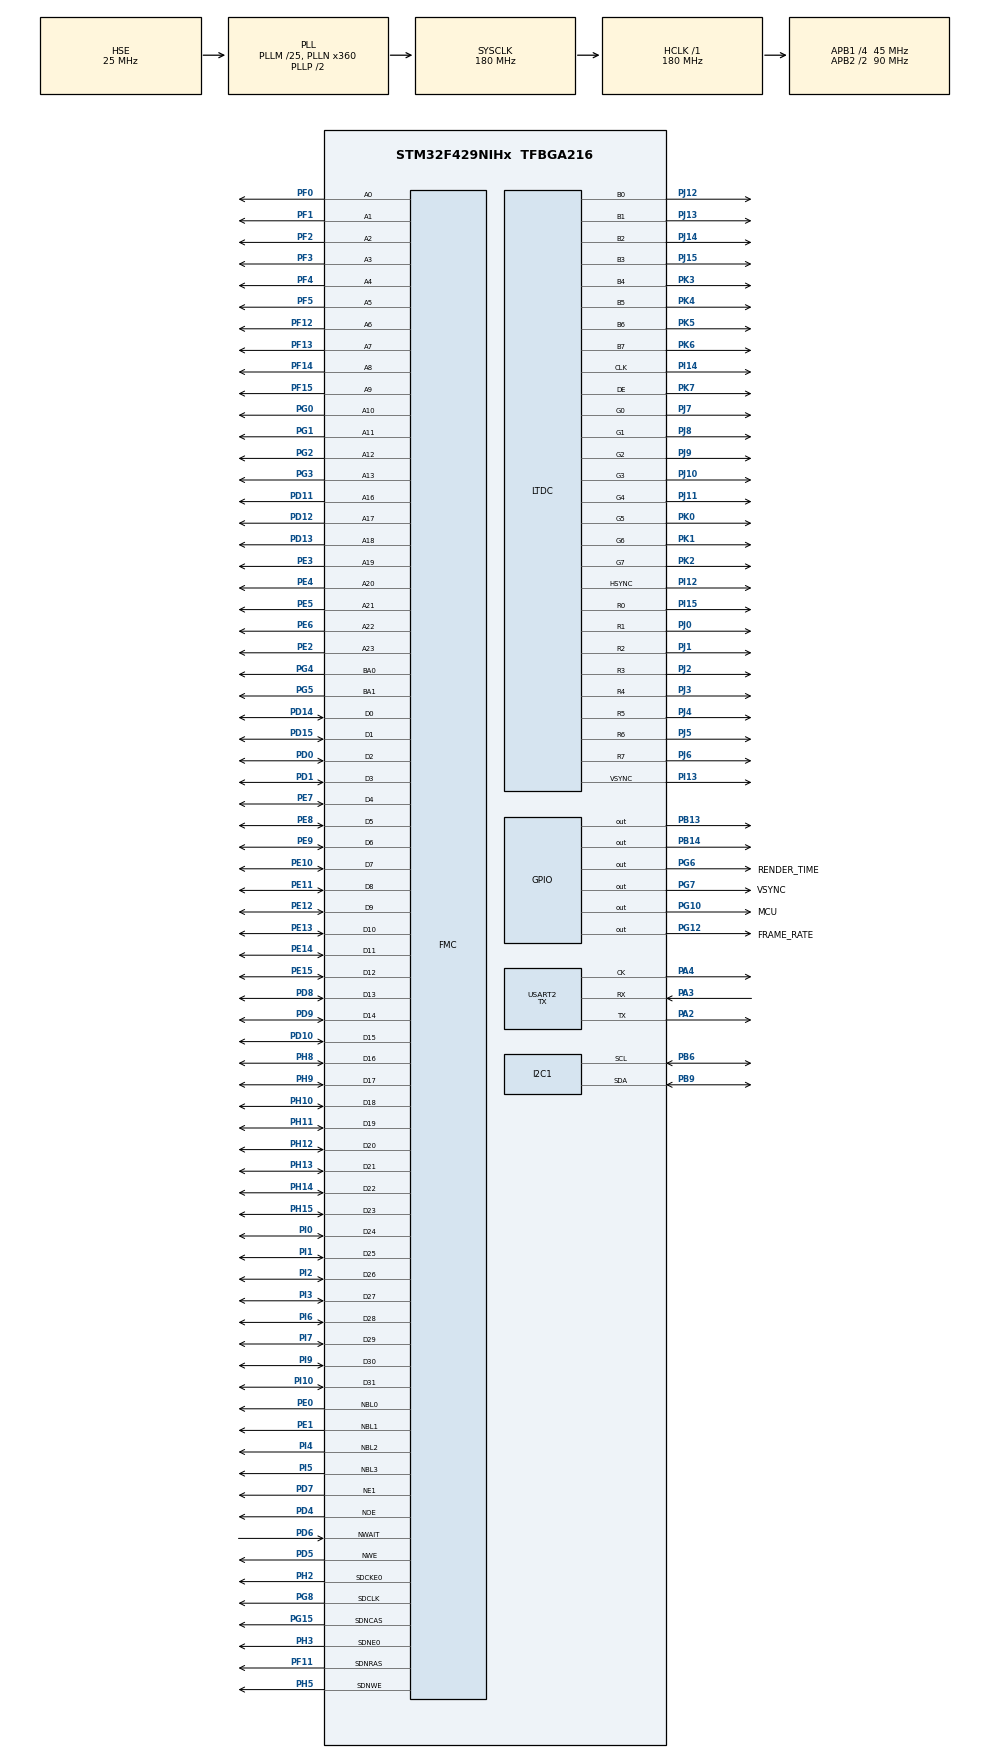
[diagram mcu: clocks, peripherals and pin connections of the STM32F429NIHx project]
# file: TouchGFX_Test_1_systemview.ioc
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FMC.AddressSetupTime1=4
FMC.BusTurnAroundDuration1=1
FMC.CASLatency1=FMC_SDRAM_CAS_LATENCY_3
FMC.ColumnBitsNumber1=FMC_SDRAM_COLUMN_BITS_NUM_9
FMC.DataSetupTime1=7
FMC.ExitSelfRefreshDelay1=7
FMC.LoadToActiveDelay1=2
FMC.RCDDelay1=3
FMC.RPDelay1=2
FMC.ReadBurst1=FMC_SDRAM_RBURST_ENABLE
FMC.RowCycleDelay1=7
FMC.SDClockPeriod1=FMC_SDRAM_CLOCK_PERIOD_2
FMC.SelfRefreshTime1=4
FMC.WriteOperation1=FMC_WRITE_OPERATION_ENABLE
FMC.WriteRecoveryTime1=2
FREERTOS.Tasks01=TouchGFXTask,24,2048,TouchGFX_Task,As weak,NULL,Dynamic,NULL,NULL
FREERTOS.configTOTAL_HEAP_SIZE=16384
FREERTOS.configUSE_APPLICATION_TASK_TAG=1
FREERTOS.configUSE_IDLE_HOOK=0
LTDC.ActiveH=272
LTDC.ActiveW=480
LTDC.Alpha_L0=255
LTDC.FBStartAdress_L0=0xC0000000
LTDC.HBP=2
LTDC.HFP=2
LTDC.HSync=41
LTDC.ImageHeight_L0=272
LTDC.ImageWidth_L0=480
LTDC.Layers=0
LTDC.PixelFormat_L0=LTDC_PIXEL_FORMAT_RGB888
LTDC.VSync=10
LTDC.WindowX1_L0=480
LTDC.WindowY1_L0=272
Mcu.Family=STM32F4
Mcu.Name=STM32F429NIHx
Mcu.Package=TFBGA216
NVIC.DMA2D_IRQn=true\:0\:0\:false\:false\:true\:true\:true\:true
NVIC.LTDC_IRQn=true\:0\:0\:false\:false\:true\:true\:true\:true
NVIC.PriorityGroup=NVIC_PRIORITYGROUP_4
NVIC.TIM6_DAC_IRQn=true\:0\:0\:false\:false\:true\:false\:false\:true
NVIC.TimeBase=TIM6_DAC_IRQn
NVIC.TimeBaseIP=TIM6
NVIC.USART2_IRQn=true\:0\:0\:false\:false\:true\:true\:true\:true
PA2.Mode=Synchronous
PA2.Signal=USART2_TX
PA3.Mode=Synchronous
PA3.Signal=USART2_RX
PA4.Mode=Synchronous
PA4.Signal=USART2_CK
PB13.Signal=GPIO_Output
PB14.Signal=GPIO_Output
PB6.GPIO_PuPdOD=GPIO_NOPULL
PB6.GPIO_Speed=GPIO_SPEED_FREQ_HIGH
PB6.Mode=I2C
PB6.Signal=I2C1_SCL
PB9.GPIO_PuPdOD=GPIO_NOPULL
PB9.GPIO_Speed=GPIO_SPEED_FREQ_HIGH
PB9.Mode=I2C
PB9.Signal=I2C1_SDA
PD0.Signal=FMC_D2_DA2
PD1.Signal=FMC_D3_DA3
PD10.Signal=FMC_D15_DA15
PD11.Signal=FMC_A16_CLE
PD12.Signal=FMC_A17_ALE
PD13.Signal=FMC_A18
PD14.Signal=FMC_D0_DA0
PD15.Signal=FMC_D1_DA1
PD4.Signal=FMC_NOE
PD5.Signal=FMC_NWE
PD6.Signal=FMC_NWAIT
PD7.Mode=NorPsramChipSelect1_1
PD7.Signal=FMC_NE1
PD8.Signal=FMC_D13_DA13
PD9.Signal=FMC_D14_DA14
PE0.Signal=FMC_NBL0
PE1.Signal=FMC_NBL1
PE10.Signal=FMC_D7_DA7
PE11.Signal=FMC_D8_DA8
PE12.Signal=FMC_D9_DA9
PE13.Signal=FMC_D10_DA10
PE14.Signal=FMC_D11_DA11
PE15.Signal=FMC_D12_DA12
PE2.Signal=FMC_A23
PE3.Signal=FMC_A19
PE4.Signal=FMC_A20
PE5.Signal=FMC_A21
PE6.Signal=FMC_A22
PE7.Signal=FMC_D4_DA4
PE8.Signal=FMC_D5_DA5
PE9.Signal=FMC_D6_DA6
PF0.Signal=FMC_A0
PF1.Signal=FMC_A1
PF11.Signal=FMC_SDNRAS
PF12.Signal=FMC_A6
PF13.Signal=FMC_A7
PF14.Signal=FMC_A8
PF15.Signal=FMC_A9
PF2.Signal=FMC_A2
PF3.Signal=FMC_A3
PF4.Signal=FMC_A4
PF5.Signal=FMC_A5
PG0.Signal=FMC_A10
PG1.Signal=FMC_A11
PG10.GPIO_Label=MCU
PG10.Signal=GPIO_Output
PG12.GPIO_Label=FRAME_RATE
PG12.Signal=GPIO_Output
PG15.Signal=FMC_SDNCAS
PG2.Signal=FMC_A12
PG3.Signal=FMC_A13
PG4.Signal=FMC_A14_BA0
PG5.Signal=FMC_A15_BA1
PG6.GPIO_Label=RENDER_TIME
PG6.Signal=GPIO_Output
PG7.GPIO_Label=VSYNC
PG7.Signal=GPIO_Output
PG8.Signal=FMC_SDCLK
PH0/OSC_IN.Mode=HSE-External-Oscillator
PH0/OSC_IN.Signal=RCC_OSC_IN
PH1/OSC_OUT.Mode=HSE-External-Oscillator
PH1/OSC_OUT.Signal=RCC_OSC_OUT
PH10.Signal=FMC_D18
PH11.Signal=FMC_D19
PH12.Signal=FMC_D20
PH13.Signal=FMC_D21
PH14.Signal=FMC_D22
PH15.Signal=FMC_D23
PH2.Mode=SdramChipSelect1_1
PH2.Signal=FMC_SDCKE0
PH3.Mode=SdramChipSelect1_1
PH3.Signal=FMC_SDNE0
PH5.Signal=FMC_SDNWE
PH8.Signal=FMC_D16
PH9.Signal=FMC_D17
PI0.Signal=FMC_D24
PI1.Signal=FMC_D25
PI10.Signal=FMC_D31
PI12.Mode=RGB888
PI12.Signal=LTDC_HSYNC
PI13.Mode=RGB888
PI13.Signal=LTDC_VSYNC
PI14.Mode=RGB888
PI14.Signal=LTDC_CLK
PI15.Mode=RGB888
PI15.Signal=LTDC_R0
PI2.Signal=FMC_D26
PI3.Signal=FMC_D27
PI4.Signal=FMC_NBL2
PI5.Signal=FMC_NBL3
PI6.Signal=FMC_D28
PI7.Signal=FMC_D29
PI9.Signal=FMC_D30
PJ0.Mode=RGB888
PJ0.Signal=LTDC_R1
PJ1.Mode=RGB888
PJ1.Signal=LTDC_R2
PJ10.Mode=RGB888
PJ10.Signal=LTDC_G3
PJ11.Mode=RGB888
PJ11.Signal=LTDC_G4
PJ12.Mode=RGB888
PJ12.Signal=LTDC_B0
PJ13.Mode=RGB888
PJ13.Signal=LTDC_B1
PJ14.Mode=RGB888
PJ14.Signal=LTDC_B2
PJ15.Mode=RGB888
PJ15.Signal=LTDC_B3
PJ2.Mode=RGB888
PJ2.Signal=LTDC_R3
PJ3.Mode=RGB888
PJ3.Signal=LTDC_R4
PJ4.Mode=RGB888
PJ4.Signal=LTDC_R5
PJ5.Mode=RGB888
PJ5.Signal=LTDC_R6
PJ6.Mode=RGB888
PJ6.Signal=LTDC_R7
PJ7.Mode=RGB888
PJ7.Signal=LTDC_G0
PJ8.Mode=RGB888
PJ8.Signal=LTDC_G1
PJ9.Mode=RGB888
PJ9.Signal=LTDC_G2
PK0.Mode=RGB888
PK0.Signal=LTDC_G5
PK1.Mode=RGB888
PK1.Signal=LTDC_G6
PK2.Mode=RGB888
PK2.Signal=LTDC_G7
PK3.Mode=RGB888
PK3.Signal=LTDC_B4
PK4.Mode=RGB888
PK4.Signal=LTDC_B5
PK5.Mode=RGB888
PK5.Signal=LTDC_B6
PK6.Mode=RGB888
PK6.Signal=LTDC_B7
PK7.Mode=RGB888
PK7.Signal=LTDC_DE
ProjectManager.HeapSize=0x1000
ProjectManager.StackSize=0x1000
ProjectManager.TargetToolchain=STM32CubeIDE
RCC.48MHZClocksFreq_Value=90000000
RCC.AHBFreq_Value=180000000
RCC.APB1CLKDivider=RCC_HCLK_DIV4
RCC.APB1Freq_Value=45000000
RCC.APB1TimFreq_Value=90000000
RCC.APB2CLKDivider=RCC_HCLK_DIV2
RCC.APB2Freq_Value=90000000
RCC.APB2TimFreq_Value=180000000
RCC.CortexFreq_Value=180000000
RCC.HCLKFreq_Value=180000000
RCC.HSE_VALUE=25000000
RCC.HSI_VALUE=16000000
RCC.LSE_VALUE=32768
RCC.PLLM=25
RCC.PLLN=360
RCC.PLLSAIDivR=RCC_PLLSAIDIVR_4
RCC.PLLSAIN=192
RCC.PLLSAIR=5
RCC.PLLSourceVirtual=RCC_PLLSOURCE_HSE
RCC.SYSCLKFreq_VALUE=180000000
RCC.SYSCLKSource=RCC_SYSCLKSOURCE_PLLCLK
RCC.VCOOutputFreq_Value=360000000
SH.FMC_A0.0=FMC_A0,12b-sda1
SH.FMC_A0.1=FMC_A0,24b-a1
SH.FMC_A1.0=FMC_A1,12b-sda1
SH.FMC_A1.1=FMC_A1,24b-a1
SH.FMC_A10.0=FMC_A10,12b-sda1
SH.FMC_A10.1=FMC_A10,24b-a1
SH.FMC_A11.0=FMC_A11,12b-sda1
SH.FMC_A11.1=FMC_A11,24b-a1
SH.FMC_A12.0=FMC_A12,24b-a1
SH.FMC_A13.0=FMC_A13,24b-a1
SH.FMC_A14_BA0.0=FMC_BA0,FourSdramBanks1
SH.FMC_A14_BA0.1=FMC_A14,24b-a1
SH.FMC_A15_BA1.0=FMC_BA1,FourSdramBanks1
SH.FMC_A15_BA1.1=FMC_A15,24b-a1
SH.FMC_A16_CLE.0=FMC_A16,24b-a1
SH.FMC_A17_ALE.0=FMC_A17,24b-a1
SH.FMC_A18.0=FMC_A18,24b-a1
SH.FMC_A19.0=FMC_A19,24b-a1
SH.FMC_A2.0=FMC_A2,12b-sda1
SH.FMC_A2.1=FMC_A2,24b-a1
SH.FMC_A20.0=FMC_A20,24b-a1
SH.FMC_A21.0=FMC_A21,24b-a1
SH.FMC_A22.0=FMC_A22,24b-a1
SH.FMC_A23.0=FMC_A23,24b-a1
SH.FMC_A3.0=FMC_A3,12b-sda1
SH.FMC_A3.1=FMC_A3,24b-a1
SH.FMC_A4.0=FMC_A4,12b-sda1
SH.FMC_A4.1=FMC_A4,24b-a1
SH.FMC_A5.0=FMC_A5,12b-sda1
SH.FMC_A5.1=FMC_A5,24b-a1
SH.FMC_A6.0=FMC_A6,12b-sda1
SH.FMC_A6.1=FMC_A6,24b-a1
SH.FMC_A7.0=FMC_A7,12b-sda1
SH.FMC_A7.1=FMC_A7,24b-a1
SH.FMC_A8.0=FMC_A8,12b-sda1
SH.FMC_A8.1=FMC_A8,24b-a1
SH.FMC_A9.0=FMC_A9,12b-sda1
SH.FMC_A9.1=FMC_A9,24b-a1
SH.FMC_D0_DA0.0=FMC_D0,sd-32b-d1
SH.FMC_D0_DA0.1=FMC_D0,16b-d1
SH.FMC_D10_DA10.0=FMC_D10,sd-32b-d1
SH.FMC_D10_DA10.1=FMC_D10,16b-d1
SH.FMC_D11_DA11.0=FMC_D11,sd-32b-d1
SH.FMC_D11_DA11.1=FMC_D11,16b-d1
SH.FMC_D12_DA12.0=FMC_D12,sd-32b-d1
SH.FMC_D12_DA12.1=FMC_D12,16b-d1
SH.FMC_D13_DA13.0=FMC_D13,sd-32b-d1
SH.FMC_D13_DA13.1=FMC_D13,16b-d1
SH.FMC_D14_DA14.0=FMC_D14,sd-32b-d1
SH.FMC_D14_DA14.1=FMC_D14,16b-d1
SH.FMC_D15_DA15.0=FMC_D15,sd-32b-d1
SH.FMC_D15_DA15.1=FMC_D15,16b-d1
SH.FMC_D16.0=FMC_D16,sd-32b-d1
SH.FMC_D17.0=FMC_D17,sd-32b-d1
SH.FMC_D18.0=FMC_D18,sd-32b-d1
SH.FMC_D19.0=FMC_D19,sd-32b-d1
SH.FMC_D1_DA1.0=FMC_D1,sd-32b-d1
SH.FMC_D1_DA1.1=FMC_D1,16b-d1
SH.FMC_D20.0=FMC_D20,sd-32b-d1
SH.FMC_D21.0=FMC_D21,sd-32b-d1
SH.FMC_D22.0=FMC_D22,sd-32b-d1
SH.FMC_D23.0=FMC_D23,sd-32b-d1
SH.FMC_D24.0=FMC_D24,sd-32b-d1
SH.FMC_D25.0=FMC_D25,sd-32b-d1
SH.FMC_D26.0=FMC_D26,sd-32b-d1
SH.FMC_D27.0=FMC_D27,sd-32b-d1
SH.FMC_D28.0=FMC_D28,sd-32b-d1
SH.FMC_D29.0=FMC_D29,sd-32b-d1
SH.FMC_D2_DA2.0=FMC_D2,sd-32b-d1
SH.FMC_D2_DA2.1=FMC_D2,16b-d1
SH.FMC_D30.0=FMC_D30,sd-32b-d1
SH.FMC_D31.0=FMC_D31,sd-32b-d1
SH.FMC_D3_DA3.0=FMC_D3,sd-32b-d1
SH.FMC_D3_DA3.1=FMC_D3,16b-d1
SH.FMC_D4_DA4.0=FMC_D4,sd-32b-d1
SH.FMC_D4_DA4.1=FMC_D4,16b-d1
SH.FMC_D5_DA5.0=FMC_D5,sd-32b-d1
SH.FMC_D5_DA5.1=FMC_D5,16b-d1
SH.FMC_D6_DA6.0=FMC_D6,sd-32b-d1
SH.FMC_D6_DA6.1=FMC_D6,16b-d1
SH.FMC_D7_DA7.0=FMC_D7,sd-32b-d1
SH.FMC_D7_DA7.1=FMC_D7,16b-d1
SH.FMC_D8_DA8.0=FMC_D8,sd-32b-d1
SH.FMC_D8_DA8.1=FMC_D8,16b-d1
SH.FMC_D9_DA9.0=FMC_D9,sd-32b-d1
SH.FMC_D9_DA9.1=FMC_D9,16b-d1
SH.FMC_NBL0.0=FMC_NBL0,Sd4ByteEnable1
SH.FMC_NBL1.0=FMC_NBL1,Sd4ByteEnable1
SH.FMC_NBL2.0=FMC_NBL2,Sd4ByteEnable1
SH.FMC_NBL3.0=FMC_NBL3,Sd4ByteEnable1
SH.FMC_NOE.0=FMC_NOE,NorFlash1
SH.FMC_NWAIT.0=FMC_NWAIT,AsynchronousWait1
SH.FMC_NWE.0=FMC_NWE,NorFlash1
SH.FMC_SDCLK.0=FMC_SDCLK,12b-sda1
SH.FMC_SDNCAS.0=FMC_SDNCAS,12b-sda1
SH.FMC_SDNRAS.0=FMC_SDNRAS,12b-sda1
SH.FMC_SDNWE.0=FMC_SDNWE,12b-sda1
STMicroelectronics.X-CUBE-TOUCHGFX.4.14.0.ApplicationCcGraphicsJjApplication=TouchGFXOoGenerator
STMicroelectronics.X-CUBE-TOUCHGFX.4.14.0.tgfx_address1=0xC0000000
STMicroelectronics.X-CUBE-TOUCHGFX.4.14.0.tgfx_address2=0xC005FA01
STMicroelectronics.X-CUBE-TOUCHGFX.4.14.0.tgfx_buffering_strategy=Double
STMicroelectronics.X-CUBE-TOUCHGFX.4.14.0.tgfx_custom_height=272
STMicroelectronics.X-CUBE-TOUCHGFX.4.14.0.tgfx_display_interface=disp_ltdc
STMicroelectronics.X-CUBE-TOUCHGFX.4.14.0.tgfx_hardware_accelerator=dma_2d
STMicroelectronics.X-CUBE-TOUCHGFX.4.14.0.tgfx_location=By Address
STMicroelectronics.X-CUBE-TOUCHGFX.4.14.0.tgfx_pixel_format=RGB888\:24
STMicroelectronics.X-CUBE-TOUCHGFX.4.14.0.tgfx_vsync=vsync_ltdc
USART2.CLKLastBit=USART_LASTBIT_ENABLE
USART2.Mode=MODE_TX
USART2.VirtualMode=VM_SYNC
USART2.WordLength=WORDLENGTH_9B
VP_CRC_VS_CRC.Mode=CRC_Activate
VP_DMA2D_VS_DMA2D.Mode=DMA2D_Activate
VP_FREERTOS_VS_CMSIS_V2.Mode=CMSIS_V2
VP_STMicroelectronics.X-CUBE-TOUCHGFX_VS_GraphicsJjApplication_4.14.0.Mode=GraphicsJjApplication
VP_SYS_VS_tim6.Mode=TIM6
board=custom

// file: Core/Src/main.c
/* USER CODE BEGIN Header */
/**
  ******************************************************************************
  * @file           : main.c
  * @brief          : Main program body
  ******************************************************************************
  * @attention
  *
  * <h2><center>&copy; Copyright (c) 2020 STMicroelectronics.
  * All rights reserved.</center></h2>
  *
  * This software component is licensed by ST under BSD 3-Clause license,
  * the "License"; You may not use this file except in compliance with the
  * License. You may obtain a copy of the License at:
  *                        opensource.org/licenses/BSD-3-Clause
  *
  ******************************************************************************
  */
/* USER CODE END Header */

#include "main.h"
#include "cmsis_os.h"
#include "app_touchgfx.h"

/* USER CODE BEGIN PD */
#define REFRESH_COUNT                    ((uint32_t)0x0569)   /* SDRAM refresh counter (90Mhz SD clock) */
#define SDRAM_TIMEOUT     ((uint32_t)0xFFFF)
/**
  * @brief  FMC SDRAM Mode definition register defines
  */
#define SDRAM_MODEREG_BURST_LENGTH_1             ((uint16_t)0x0000)
#define SDRAM_MODEREG_BURST_LENGTH_2             ((uint16_t)0x0001)
#define SDRAM_MODEREG_BURST_LENGTH_4             ((uint16_t)0x0002)
#define SDRAM_MODEREG_BURST_LENGTH_8             ((uint16_t)0x0004)
#define SDRAM_MODEREG_BURST_TYPE_SEQUENTIAL      ((uint16_t)0x0000)
#define SDRAM_MODEREG_BURST_TYPE_INTERLEAVED     ((uint16_t)0x0008)
#define SDRAM_MODEREG_CAS_LATENCY_2              ((uint16_t)0x0020)
#define SDRAM_MODEREG_CAS_LATENCY_3              ((uint16_t)0x0030)
#define SDRAM_MODEREG_OPERATING_MODE_STANDARD    ((uint16_t)0x0000)
#define SDRAM_MODEREG_WRITEBURST_MODE_PROGRAMMED ((uint16_t)0x0000)
#define SDRAM_MODEREG_WRITEBURST_MODE_SINGLE     ((uint16_t)0x0200)

#define LCD_RST_HIGH	(GPIOB->BSRR |= GPIO_PIN_13)
#define LCD_RST_LOW		(GPIOB->BSRR |= (uint32_t)GPIO_PIN_13 << 16U)
#define LCD_CSX_HIGH	(GPIOB->BSRR |= GPIO_PIN_14)
#define LCD_CSX_LOW		(GPIOB->BSRR |= (uint32_t)GPIO_PIN_14 << 16U)
/* USER CODE END PD */

CRC_HandleTypeDef hcrc;

DMA2D_HandleTypeDef hdma2d;

I2C_HandleTypeDef hi2c1;

LTDC_HandleTypeDef hltdc;

USART_HandleTypeDef husart2;

NOR_HandleTypeDef hnor1;
SDRAM_HandleTypeDef hsdram1;

/* Definitions for TouchGFXTask */
osThreadId_t TouchGFXTaskHandle;
const osThreadAttr_t TouchGFXTask_attributes = {
  .name = "TouchGFXTask",
  .priority = (osPriority_t) osPriorityNormal,
  .stack_size = 2048
};

void SystemClock_Config(void);
static void MX_GPIO_Init(void);
static void MX_FMC_Init(void);
static void MX_CRC_Init(void);
static void MX_LTDC_Init(void);
static void MX_DMA2D_Init(void);
static void MX_I2C1_Init(void);
static void MX_USART2_Init(void);
void TouchGFX_Task(void *argument);

/* USER CODE BEGIN PFP */
static void BSP_SDRAM_Initialization_sequence(uint32_t RefreshCount);
static void LCD_init(void);
static void SPI_WriteComm(uint8_t data);
static void SPI_WriteData(uint8_t data);
static uint8_t Bit_Reversal(uint8_t v);
void HAL_USART_TxCpltCallback(USART_HandleTypeDef *husart);
/* USER CODE END PFP */

int main(void)
{
  /* USER CODE BEGIN 1 */
#ifdef USE_SEGGER
	DWT->CTRL |= (1 << 0);    // Enable Cycle Counter for SEGGER
#endif
  /* USER CODE END 1 */

  /* MCU Configuration--------------------------------------------------------*/

  /* Reset of all peripherals, Initializes the Flash interface and the Systick. */
  HAL_Init();

  /* Configure the system clock */
  SystemClock_Config();

  /* USER CODE BEGIN SysInit */
    // LCD_init(); must be inserted before MX_TouchGFX_Init();
  /* USER CODE END SysInit */

  /* Initialize all configured peripherals */
  MX_GPIO_Init();
  MX_FMC_Init();
  MX_CRC_Init();
  MX_LTDC_Init();
  MX_DMA2D_Init();
  MX_I2C1_Init();
  MX_USART2_Init();
  LCD_init();
  MX_TouchGFX_Init();
  /* Init scheduler */
  osKernelInitialize();

  /* USER CODE BEGIN RTOS_QUEUES */
  /* add queues, ... */
#ifdef USE_SEGGER
  SEGGER_SYSVIEW_Conf();
  SEGGER_SYSVIEW_Start();
#endif
  /* USER CODE END RTOS_QUEUES */

  /* Create the thread(s) */
  /* creation of TouchGFXTask */
  TouchGFXTaskHandle = osThreadNew(TouchGFX_Task, NULL, &TouchGFXTask_attributes);

  /* Start scheduler */
  osKernelStart();

  /* We should never get here as control is now taken by the scheduler */

  /* Infinite loop */
  while (1)
  {

  }
}

void SystemClock_Config(void)
{
  RCC_OscInitTypeDef RCC_OscInitStruct = {0};
  RCC_ClkInitTypeDef RCC_ClkInitStruct = {0};
  RCC_PeriphCLKInitTypeDef PeriphClkInitStruct = {0};

  /** Configure the main internal regulator output voltage
  */
  __HAL_RCC_PWR_CLK_ENABLE();
  __HAL_PWR_VOLTAGESCALING_CONFIG(PWR_REGULATOR_VOLTAGE_SCALE1);
  /** Initializes the CPU, AHB and APB busses clocks
  */
  RCC_OscInitStruct.OscillatorType = RCC_OSCILLATORTYPE_HSE;
  RCC_OscInitStruct.HSEState = RCC_HSE_ON;
  RCC_OscInitStruct.PLL.PLLState = RCC_PLL_ON;
  RCC_OscInitStruct.PLL.PLLSource = RCC_PLLSOURCE_HSE;
  RCC_OscInitStruct.PLL.PLLM = 25;
  RCC_OscInitStruct.PLL.PLLN = 360;
  RCC_OscInitStruct.PLL.PLLP = RCC_PLLP_DIV2;
  RCC_OscInitStruct.PLL.PLLQ = 4;
  if (HAL_RCC_OscConfig(&RCC_OscInitStruct) != HAL_OK)
  {
    Error_Handler();
  }
  /** Activate the Over-Drive mode
  */
  if (HAL_PWREx_EnableOverDrive() != HAL_OK)
  {
    Error_Handler();
  }
  /** Initializes the CPU, AHB and APB busses clocks
  */
  RCC_ClkInitStruct.ClockType = RCC_CLOCKTYPE_HCLK|RCC_CLOCKTYPE_SYSCLK
                              |RCC_CLOCKTYPE_PCLK1|RCC_CLOCKTYPE_PCLK2;
  RCC_ClkInitStruct.SYSCLKSource = RCC_SYSCLKSOURCE_PLLCLK;
  RCC_ClkInitStruct.AHBCLKDivider = RCC_SYSCLK_DIV1;
  RCC_ClkInitStruct.APB1CLKDivider = RCC_HCLK_DIV4;
  RCC_ClkInitStruct.APB2CLKDivider = RCC_HCLK_DIV2;

  if (HAL_RCC_ClockConfig(&RCC_ClkInitStruct, FLASH_LATENCY_5) != HAL_OK)
  {
    Error_Handler();
  }
  PeriphClkInitStruct.PeriphClockSelection = RCC_PERIPHCLK_LTDC;
  PeriphClkInitStruct.PLLSAI.PLLSAIN = 192;
  PeriphClkInitStruct.PLLSAI.PLLSAIR = 5;   //4: LCD_CLK=12MHz
  PeriphClkInitStruct.PLLSAIDivR = RCC_PLLSAIDIVR_4;
  if (HAL_RCCEx_PeriphCLKConfig(&PeriphClkInitStruct) != HAL_OK)
  {
    Error_Handler();
  }
}

static void MX_CRC_Init(void)
{

  hcrc.Instance = CRC;
  if (HAL_CRC_Init(&hcrc) != HAL_OK)
  {
    Error_Handler();
  }

}

static void MX_DMA2D_Init(void)
{

  hdma2d.Instance = DMA2D;
  hdma2d.Init.Mode = DMA2D_M2M;
  hdma2d.Init.ColorMode = DMA2D_OUTPUT_ARGB8888;
  hdma2d.Init.OutputOffset = 0;
  hdma2d.LayerCfg[1].InputOffset = 0;
  hdma2d.LayerCfg[1].InputColorMode = DMA2D_INPUT_ARGB8888;
  hdma2d.LayerCfg[1].AlphaMode = DMA2D_NO_MODIF_ALPHA;
  hdma2d.LayerCfg[1].InputAlpha = 0;
  if (HAL_DMA2D_Init(&hdma2d) != HAL_OK)
  {
    Error_Handler();
  }
  if (HAL_DMA2D_ConfigLayer(&hdma2d, 1) != HAL_OK)
  {
    Error_Handler();
  }

}

static void MX_I2C1_Init(void)
{

  /* USER CODE BEGIN I2C1_Init 0 */
  HAL_I2C_DeInit(&hi2c1);
  /* USER CODE END I2C1_Init 0 */

  hi2c1.Instance = I2C1;
  hi2c1.Init.ClockSpeed = 100000;
  hi2c1.Init.DutyCycle = I2C_DUTYCYCLE_2;
  hi2c1.Init.OwnAddress1 = 0;
  hi2c1.Init.AddressingMode = I2C_ADDRESSINGMODE_7BIT;
  hi2c1.Init.DualAddressMode = I2C_DUALADDRESS_DISABLE;
  hi2c1.Init.OwnAddress2 = 0;
  hi2c1.Init.GeneralCallMode = I2C_GENERALCALL_DISABLE;
  hi2c1.Init.NoStretchMode = I2C_NOSTRETCH_DISABLE;
  if (HAL_I2C_Init(&hi2c1) != HAL_OK)
  {
    Error_Handler();
  }
  /** Configure Analogue filter
  */
  if (HAL_I2CEx_ConfigAnalogFilter(&hi2c1, I2C_ANALOGFILTER_ENABLE) != HAL_OK)
  {
    Error_Handler();
  }
  /** Configure Digital filter
  */
  if (HAL_I2CEx_ConfigDigitalFilter(&hi2c1, 0) != HAL_OK)
  {
    Error_Handler();
  }

}

static void MX_LTDC_Init(void)
{

  LTDC_LayerCfgTypeDef pLayerCfg = {0};

  hltdc.Instance = LTDC;
  hltdc.Init.HSPolarity = LTDC_HSPOLARITY_AL;
  hltdc.Init.VSPolarity = LTDC_VSPOLARITY_AL;
  hltdc.Init.DEPolarity = LTDC_DEPOLARITY_AL;
  hltdc.Init.PCPolarity = LTDC_PCPOLARITY_IPC;

  hltdc.Init.HorizontalSync = 40;
  hltdc.Init.VerticalSync = 9;
  hltdc.Init.AccumulatedHBP = 42;
  hltdc.Init.AccumulatedVBP = 11;
  hltdc.Init.AccumulatedActiveW = 522;
  hltdc.Init.AccumulatedActiveH = 283;
  hltdc.Init.TotalWidth = 524;
  hltdc.Init.TotalHeigh = 285;

  /*
  hltdc.Init.HorizontalSync = 3;
  hltdc.Init.VerticalSync = 3;
  hltdc.Init.AccumulatedHBP = 7;
  hltdc.Init.AccumulatedVBP = 7;
  hltdc.Init.AccumulatedActiveW = 487;
  hltdc.Init.AccumulatedActiveH = 327;
  hltdc.Init.TotalWidth = 491;
  hltdc.Init.TotalHeigh = 331;
  */
  hltdc.Init.Backcolor.Blue = 0;
  hltdc.Init.Backcolor.Green = 0;
  hltdc.Init.Backcolor.Red = 0;
  if (HAL_LTDC_Init(&hltdc) != HAL_OK)
  {
    Error_Handler();
  }
  pLayerCfg.WindowX0 = 0;
  pLayerCfg.WindowX1 = 480;
  pLayerCfg.WindowY0 = 0;
  pLayerCfg.WindowY1 = 272;
  pLayerCfg.PixelFormat = LTDC_PIXEL_FORMAT_RGB888;
  pLayerCfg.Alpha = 255;
  pLayerCfg.Alpha0 = 0;
  pLayerCfg.BlendingFactor1 = LTDC_BLENDING_FACTOR1_CA;
  pLayerCfg.BlendingFactor2 = LTDC_BLENDING_FACTOR2_CA;
  pLayerCfg.FBStartAdress = 0xC0000000;
  pLayerCfg.ImageWidth = 480;
  pLayerCfg.ImageHeight = 272;
  pLayerCfg.Backcolor.Blue = 0;
  pLayerCfg.Backcolor.Green = 0;
  pLayerCfg.Backcolor.Red = 0;
  if (HAL_LTDC_ConfigLayer(&hltdc, &pLayerCfg, 0) != HAL_OK)
  {
    Error_Handler();
  }

}

static void MX_USART2_Init(void)
{

  husart2.Instance = USART2;
  husart2.Init.BaudRate = 115200;
  husart2.Init.WordLength = USART_WORDLENGTH_9B;
  husart2.Init.StopBits = USART_STOPBITS_1;
  husart2.Init.Parity = USART_PARITY_NONE;
  husart2.Init.Mode = USART_MODE_TX;
  husart2.Init.CLKPolarity = USART_POLARITY_LOW;
  husart2.Init.CLKPhase = USART_PHASE_1EDGE;
  husart2.Init.CLKLastBit = USART_LASTBIT_ENABLE;
  if (HAL_USART_Init(&husart2) != HAL_OK)
  {
    Error_Handler();
  }

}

/* FMC initialization function */
static void MX_FMC_Init(void)
{

  FMC_NORSRAM_TimingTypeDef Timing = {0};
  FMC_SDRAM_TimingTypeDef SdramTiming = {0};

  /** Perform the NOR1 memory initialization sequence
  */
  hnor1.Instance = FMC_NORSRAM_DEVICE;
  hnor1.Extended = FMC_NORSRAM_EXTENDED_DEVICE;
  /* hnor1.Init */
  hnor1.Init.NSBank = FMC_NORSRAM_BANK1;
  hnor1.Init.DataAddressMux = FMC_DATA_ADDRESS_MUX_DISABLE;
  hnor1.Init.MemoryType = FMC_MEMORY_TYPE_NOR;
  hnor1.Init.MemoryDataWidth = FMC_NORSRAM_MEM_BUS_WIDTH_16;
  hnor1.Init.BurstAccessMode = FMC_BURST_ACCESS_MODE_DISABLE;
  hnor1.Init.WaitSignalPolarity = FMC_WAIT_SIGNAL_POLARITY_LOW;
  hnor1.Init.WrapMode = FMC_WRAP_MODE_DISABLE;
  hnor1.Init.WaitSignalActive = FMC_WAIT_TIMING_BEFORE_WS;
  hnor1.Init.WriteOperation = FMC_WRITE_OPERATION_ENABLE;
  hnor1.Init.WaitSignal = FMC_WAIT_SIGNAL_DISABLE;
  hnor1.Init.ExtendedMode = FMC_EXTENDED_MODE_DISABLE;
  hnor1.Init.AsynchronousWait = FMC_ASYNCHRONOUS_WAIT_ENABLE;
  hnor1.Init.WriteBurst = FMC_WRITE_BURST_DISABLE;
  hnor1.Init.ContinuousClock = FMC_CONTINUOUS_CLOCK_SYNC_ONLY;
  hnor1.Init.PageSize = FMC_PAGE_SIZE_NONE;
  /* Timing */
  Timing.AddressSetupTime = 4;
  Timing.AddressHoldTime = 15;
  Timing.DataSetupTime = 7;
  Timing.BusTurnAroundDuration = 1;
  Timing.CLKDivision = 16;
  Timing.DataLatency = 17;
  Timing.AccessMode = FMC_ACCESS_MODE_A;
  /* ExtTiming */

  if (HAL_NOR_Init(&hnor1, &Timing, NULL) != HAL_OK)
  {
    Error_Handler( );
  }

  /** Perform the SDRAM1 memory initialization sequence
  */
  hsdram1.Instance = FMC_SDRAM_DEVICE;
  /* hsdram1.Init */
  hsdram1.Init.SDBank = FMC_SDRAM_BANK1;
  hsdram1.Init.ColumnBitsNumber = FMC_SDRAM_COLUMN_BITS_NUM_9;
  hsdram1.Init.RowBitsNumber = FMC_SDRAM_ROW_BITS_NUM_12;
  hsdram1.Init.MemoryDataWidth = FMC_SDRAM_MEM_BUS_WIDTH_32;
  hsdram1.Init.InternalBankNumber = FMC_SDRAM_INTERN_BANKS_NUM_4;
  hsdram1.Init.CASLatency = FMC_SDRAM_CAS_LATENCY_3;
  hsdram1.Init.WriteProtection = FMC_SDRAM_WRITE_PROTECTION_DISABLE;
  hsdram1.Init.SDClockPeriod = FMC_SDRAM_CLOCK_PERIOD_2;
  hsdram1.Init.ReadBurst = FMC_SDRAM_RBURST_ENABLE;
  hsdram1.Init.ReadPipeDelay = FMC_SDRAM_RPIPE_DELAY_0;
  /* SdramTiming */
  SdramTiming.LoadToActiveDelay = 2;
  SdramTiming.ExitSelfRefreshDelay = 7;
  SdramTiming.SelfRefreshTime = 4;
  SdramTiming.RowCycleDelay = 7;
  SdramTiming.WriteRecoveryTime = 2;
  SdramTiming.RPDelay = 2;
  SdramTiming.RCDDelay = 3;

  if (HAL_SDRAM_Init(&hsdram1, &SdramTiming) != HAL_OK)
  {
    Error_Handler( );
  }

  /* USER CODE BEGIN FMC_Init 2 */
  /* SDRAM initialization sequence */
  BSP_SDRAM_Initialization_sequence(REFRESH_COUNT);
  /* USER CODE END FMC_Init 2 */
}

static void MX_GPIO_Init(void)
{
  GPIO_InitTypeDef GPIO_InitStruct = {0};

  /* GPIO Ports Clock Enable */
  __HAL_RCC_GPIOE_CLK_ENABLE();
  __HAL_RCC_GPIOD_CLK_ENABLE();
  __HAL_RCC_GPIOB_CLK_ENABLE();
  __HAL_RCC_GPIOG_CLK_ENABLE();
  __HAL_RCC_GPIOJ_CLK_ENABLE();
  __HAL_RCC_GPIOI_CLK_ENABLE();
  __HAL_RCC_GPIOK_CLK_ENABLE();
  __HAL_RCC_GPIOF_CLK_ENABLE();
  __HAL_RCC_GPIOH_CLK_ENABLE();
  __HAL_RCC_GPIOA_CLK_ENABLE();

  /*Configure GPIO pin Output Level */
  HAL_GPIO_WritePin(GPIOG, FRAME_RATE_Pin|MCU_Pin|VSYNC_Pin|RENDER_TIME_Pin, GPIO_PIN_RESET);

  /*Configure GPIO pin Output Level */
  HAL_GPIO_WritePin(GPIOB, GPIO_PIN_13|GPIO_PIN_14, GPIO_PIN_RESET);

  /*Configure GPIO pins : FRAME_RATE_Pin MCU_Pin VSYNC_Pin RENDER_TIME_Pin */
  GPIO_InitStruct.Pin = FRAME_RATE_Pin|MCU_Pin|VSYNC_Pin|RENDER_TIME_Pin;
  GPIO_InitStruct.Mode = GPIO_MODE_OUTPUT_PP;
  GPIO_InitStruct.Pull = GPIO_NOPULL;
  GPIO_InitStruct.Speed = GPIO_SPEED_FREQ_LOW;
  HAL_GPIO_Init(GPIOG, &GPIO_InitStruct);

  /*Configure GPIO pins : PB13 PB14 */
  GPIO_InitStruct.Pin = GPIO_PIN_13|GPIO_PIN_14;
  GPIO_InitStruct.Mode = GPIO_MODE_OUTPUT_PP;
  GPIO_InitStruct.Pull = GPIO_NOPULL;
  GPIO_InitStruct.Speed = GPIO_SPEED_FREQ_LOW;
  HAL_GPIO_Init(GPIOB, &GPIO_InitStruct);

}

/* USER CODE BEGIN 4 */

/**
  * @brief  Programs the SDRAM device.
  * @param  RefreshCount: SDRAM refresh counter value
  * @retval None
  */
void BSP_SDRAM_Initialization_sequence(uint32_t RefreshCount)
{
  FMC_SDRAM_CommandTypeDef Command = {0};
  __IO uint32_t tmpmrd = 0;

  /* Step 1: Configure a clock configuration enable command */
  Command.CommandMode            = FMC_SDRAM_CMD_CLK_ENABLE;
  Command.CommandTarget          = FMC_SDRAM_CMD_TARGET_BANK1;
  Command.AutoRefreshNumber      = 1;
  Command.ModeRegisterDefinition = 0;

  /* Send the command */
  HAL_SDRAM_SendCommand(&hsdram1, &Command, SDRAM_TIMEOUT);

  /* Step 2: Insert 100 us minimum delay */
  /* Inserted delay is equal to 1 ms due to systick time base unit (ms) */
  HAL_Delay(1);

  /* Step 3: Configure a PALL (precharge all) command */
  Command.CommandMode            = FMC_SDRAM_CMD_PALL;
  Command.CommandTarget          = FMC_SDRAM_CMD_TARGET_BANK1;
  Command.AutoRefreshNumber      = 1;
  Command.ModeRegisterDefinition = 0;

  /* Send the command */
  HAL_SDRAM_SendCommand(&hsdram1, &Command, SDRAM_TIMEOUT);

  /* Step 4: Configure an Auto Refresh command */
  Command.CommandMode            = FMC_SDRAM_CMD_AUTOREFRESH_MODE;
  Command.CommandTarget          = FMC_SDRAM_CMD_TARGET_BANK1;
  Command.AutoRefreshNumber      = 8;
  Command.ModeRegisterDefinition = 0;

  /* Send the command */
  HAL_SDRAM_SendCommand(&hsdram1, &Command, SDRAM_TIMEOUT);

  /* Step 5: Program the external memory mode register */
  tmpmrd = (uint32_t)SDRAM_MODEREG_BURST_LENGTH_1          |\
                     SDRAM_MODEREG_BURST_TYPE_SEQUENTIAL   |\
                     SDRAM_MODEREG_CAS_LATENCY_3           |\
                     SDRAM_MODEREG_OPERATING_MODE_STANDARD |\
                     SDRAM_MODEREG_WRITEBURST_MODE_SINGLE;

  Command.CommandMode            = FMC_SDRAM_CMD_LOAD_MODE;
  Command.CommandTarget          = FMC_SDRAM_CMD_TARGET_BANK1;
  Command.AutoRefreshNumber      = 1;
  Command.ModeRegisterDefinition = tmpmrd;

  /* Send the command */
  HAL_SDRAM_SendCommand(&hsdram1, &Command, SDRAM_TIMEOUT);

  /* Step 6: Set the refresh rate counter */
  /* Set the device refresh rate */
  HAL_SDRAM_ProgramRefreshRate(&hsdram1, RefreshCount);
}

static void LCD_init(void)
{
	LCD_RST_HIGH;
	HAL_Delay(1); // Delay 1ms
	LCD_RST_LOW;
	HAL_Delay(10); // Delay 10ms // This delay time is necessary
	LCD_RST_HIGH;
	HAL_Delay(120); // Delay 120 ms
	///************* Start Initial Sequence **********//

	SPI_WriteComm(0xE0);   //P-Gamma
	SPI_WriteData(0x00);
	SPI_WriteData(0x03);
	SPI_WriteData(0x0C);
	SPI_WriteData(0x09);
	SPI_WriteData(0x17);
	SPI_WriteData(0x09);
	SPI_WriteData(0x3E);
	SPI_WriteData(0x89);
	SPI_WriteData(0x49);
	SPI_WriteData(0x08);
	SPI_WriteData(0x0D);
	SPI_WriteData(0x0A);
	SPI_WriteData(0x13);
	SPI_WriteData(0x15);
	SPI_WriteData(0x0F);

	SPI_WriteComm(0XE1);   //N-Gamma
	SPI_WriteData(0x00);
	SPI_WriteData(0x11);
	SPI_WriteData(0x15);
	SPI_WriteData(0x03);
	SPI_WriteData(0x0F);
	SPI_WriteData(0x05);
	SPI_WriteData(0x2D);
	SPI_WriteData(0x34);
	SPI_WriteData(0x41);
	SPI_WriteData(0x02);

	SPI_WriteData(0x0B);
	SPI_WriteData(0x0A);
	SPI_WriteData(0x33);
	SPI_WriteData(0x37);
	SPI_WriteData(0x0F);

	SPI_WriteComm(0XC0);  //Power Control 1
	SPI_WriteData(0x17);  //Vreg1out
	SPI_WriteData(0x15);  //Verg2out

	SPI_WriteComm(0xC1);  //Power Control 2
	SPI_WriteData(0x41);  //VGH,VGL

	SPI_WriteComm(0xC5);  //Power Control 3
	SPI_WriteData(0x00);
	SPI_WriteData(0x12);  //Vcom
	SPI_WriteData(0x80);

	SPI_WriteComm(0x36);   //Memory Access
	//SPI_WriteData(0x08); 		// MY(D7),MX(D6),MV(D5)=000 : rb mirror
	//SPI_WriteData(0x48); 		// MY(D7),MX(D6),MV(D5)=010 : ru normal
	//SPI_WriteData(0xC8);   	// MY(D7),MX(D6),MV(D5)=110 : lu mirror
	//SPI_WriteData(0x28);   	// MY(D7),MX(D6),MV(D5)=001 : rb normal flickering, display weird
	SPI_WriteData(0xE8);   	// MY(D7),MX(D6),MV(D5)=111 : ok but flickering
	//SPI_WriteData(0xA8);   	// MY(D7),MX(D6),MV(D5)=101
	//SPI_WriteData(0x88);   		// MY(D7),MX(D6),MV(D5)=100

	SPI_WriteComm(0x2A);	// Column Address Set
	SPI_WriteData(0x00);	// SC[15:8]
	SPI_WriteData(0x00);	// SC[7:0]
	SPI_WriteData(0x01);	// EC[15:8]
	SPI_WriteData(0xDF);	// EC[7:0]   --> 479 = 0x1DF

	SPI_WriteComm(0x2B);	// Page Address Set
	SPI_WriteData(0x00);	// SP[15:8]
	SPI_WriteData(0x00);	// SP[7:0]
	SPI_WriteData(0x01);	// EP[15:8]
	SPI_WriteData(0x3F);	// EP[7:0]	 --> 319 = 0x13F

	SPI_WriteComm(0x3A);   // Interface Pixel Format
	SPI_WriteData(0x66);	// 18 bits / pixel

	SPI_WriteComm(0XB0);   // Interface Mode Control
	SPI_WriteData(0x00);

	SPI_WriteComm(0xB1);   //Frame rate
	SPI_WriteData(0xA0);  	//60Hz

	SPI_WriteComm(0xB4);   //Display Inversion Control
	SPI_WriteData(0x02);  //2-dot

	SPI_WriteComm(0XB6);  //RGB/MCU Interface Control
	SPI_WriteData(0x20);  //MCU 02
	SPI_WriteData(0x02);  //Source,Gate scan direction

	SPI_WriteComm(0XE9);   // Set Image Function
	SPI_WriteData(0x00);  // Disable 24 bit data input

	SPI_WriteComm(0xF7);    // Adjust Control
	SPI_WriteData(0xA9);
	SPI_WriteData(0x51);
	SPI_WriteData(0x2C);
	SPI_WriteData(0x82);   // D7 stream, loose

	SPI_WriteComm(0x11);   //Sleep out
	HAL_Delay(120);
	SPI_WriteComm(0x29);  //Display on
	//SPI_WriteComm(0x2C);  //Memory Write
}

static void SPI_WriteComm(uint8_t comm)
{
	uint8_t result = 0;
	uint16_t result16[]={0};

	result = Bit_Reversal(comm);
	result16[0] = ((uint16_t)result << 1) | 0 ;
	  while (HAL_USART_GetState(&husart2) != HAL_USART_STATE_READY)
	  {
	  }
	  LCD_CSX_LOW;
	  HAL_Delay(1);
	if(HAL_USART_Transmit_IT(&husart2, (uint8_t*)result16, 1)!= HAL_OK)
	  {
		//BSP_LED_On(LED3);
		while(1)
		{
		}
	  }
}

static void SPI_WriteData(uint8_t data)
{
	uint8_t result = 0;
	uint16_t result16[]={0};

	result = Bit_Reversal(data);
	result16[0] = ((uint16_t)result << 1) | 1 ;
	  while (HAL_USART_GetState(&husart2) != HAL_USART_STATE_READY)
	  {
	  }
	  LCD_CSX_LOW;
	  HAL_Delay(1);
	if(HAL_USART_Transmit_IT(&husart2, (uint8_t*)result16, 1)!= HAL_OK)
	  {
		//BSP_LED_On(LED3);
		while(1)
		{
		}
	  }
}

static uint8_t Bit_Reversal(uint8_t v)
{
	uint8_t result = 0;

	result = ((v << 7) & 0x80) | ((v << 5) & 0x40) | ((v << 3) & 0x20) | ((v << 1) & 0x10) |\
			((v >> 7) & 0x01) | ((v >> 5) & 0x02) | ((v >> 3) & 0x04) | ((v >> 1) & 0x08);
	return result;
}

void HAL_USART_TxCpltCallback(USART_HandleTypeDef *husart)
{
	LCD_CSX_HIGH;
}
/* USER CODE END 4 */

__weak void TouchGFX_Task(void *argument)
{
  for(;;)
  {
    osDelay(1);
  }
}

void HAL_TIM_PeriodElapsedCallback(TIM_HandleTypeDef *htim)
{
  if (htim->Instance == TIM6) {
    HAL_IncTick();
  }
}

void Error_Handler(void)
{
}

/************************ (C) COPYRIGHT STMicroelectronics *****END OF FILE****/
